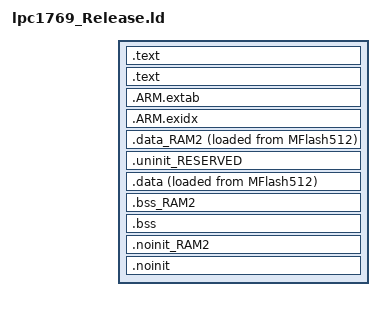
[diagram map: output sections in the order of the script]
/*
 * GENERATED FILE - DO NOT EDIT
 * (c) Code Red Technologies Ltd, 2008-13
 * (c) NXP Semiconductors 2013-2014
 * Generated linker script file for LPC1769
 * Created from generic_c.ld (LPCXpresso v7.5 (0 [Build 254] [2014-10-31] ))
 * By LPCXpresso v7.5.0 [Build 254] [2014-10-31]  on Fri Nov 21 18:51:49 CET 2014
 */


INCLUDE "lpc1769_Release_lib.ld"
INCLUDE "lpc1769_Release_mem.ld"

ENTRY(ResetISR)

SECTIONS
{

    /* MAIN TEXT SECTION */    
    .text : ALIGN(4)
    {
        FILL(0xff)
        __vectors_start__ = ABSOLUTE(.) ;
        KEEP(*(.isr_vector))
        
        /* Global Section Table */
        . = ALIGN(4) ;
        __section_table_start = .;
        __data_section_table = .;
        LONG(LOADADDR(.data));
        LONG(    ADDR(.data));
        LONG(  SIZEOF(.data));
        LONG(LOADADDR(.data_RAM2));
        LONG(    ADDR(.data_RAM2));
        LONG(  SIZEOF(.data_RAM2));
        __data_section_table_end = .;
        __bss_section_table = .;
        LONG(    ADDR(.bss));
        LONG(  SIZEOF(.bss));
        LONG(    ADDR(.bss_RAM2));
        LONG(  SIZEOF(.bss_RAM2));
        __bss_section_table_end = .;
        __section_table_end = . ;
        /* End of Global Section Table */
        

        *(.after_vectors*)
        
    } >MFlash512
    
    .text : ALIGN(4)    
    {
         *(.text*)
        *(.rodata .rodata.* .constdata .constdata.*)
        . = ALIGN(4);
        
    } > MFlash512

    /*
     * for exception handling/unwind - some Newlib functions (in common
     * with C++ and STDC++) use this. 
     */
    .ARM.extab : ALIGN(4)
    {
    	*(.ARM.extab* .gnu.linkonce.armextab.*)
    } > MFlash512
    __exidx_start = .;
    
    .ARM.exidx : ALIGN(4)
    {
    	*(.ARM.exidx* .gnu.linkonce.armexidx.*)
    } > MFlash512
    __exidx_end = .;
    
    _etext = .;
        
    
    /* DATA section for RamAHB32 */
    .data_RAM2 : ALIGN(4)
    {
       FILL(0xff)
       *(.ramfunc.$RAM2)
       *(.ramfunc.$RamAHB32)
    	*(.data.$RAM2*)
    	*(.data.$RamAHB32*)
       . = ALIGN(4) ;
    } > RamAHB32 AT>MFlash512
    
    /* MAIN DATA SECTION */
    

    .uninit_RESERVED : ALIGN(4)
    {
        KEEP(*(.bss.$RESERVED*))
        . = ALIGN(4) ;
        _end_uninit_RESERVED = .;
    } > RamLoc32

	
	/* Main DATA section (RamLoc32) */
	.data : ALIGN(4)
	{
	   FILL(0xff)
	   _data = . ;
	   *(vtable)
	   *(.ramfunc*)
	   *(.data*)
	   . = ALIGN(4) ;
	   _edata = . ;
	} > RamLoc32 AT>MFlash512

    /* BSS section for RamAHB32 */
    .bss_RAM2 : ALIGN(4)
    {
    	*(.bss.$RAM2*)
    	*(.bss.$RamAHB32*)
       . = ALIGN(4) ;
    } > RamAHB32

    /* MAIN BSS SECTION */
    .bss : ALIGN(4)
    {
        _bss = .;
        *(.bss*)
        *(COMMON)
        . = ALIGN(4) ;
        _ebss = .;
        PROVIDE(end = .);
    } > RamLoc32
        
    /* NOINIT section for RamAHB32 */
    .noinit_RAM2 (NOLOAD) : ALIGN(4)
    {
    	*(.noinit.$RAM2*)
    	*(.noinit.$RamAHB32*)
       . = ALIGN(4) ;
    } > RamAHB32 
    
    /* DEFAULT NOINIT SECTION */
    .noinit (NOLOAD): ALIGN(4)
    {
        _noinit = .;
        *(.noinit*) 
         . = ALIGN(4) ;
        _end_noinit = .;
    } > RamLoc32
    
    PROVIDE(_pvHeapStart = DEFINED(__user_heap_base) ? __user_heap_base : .);
    PROVIDE(_vStackTop = DEFINED(__user_stack_top) ? __user_stack_top : __top_RamLoc32 - 0);
}
